# RTS5921 register map
Vendor: Realtek Semiconductor Corp.; Series: RTS5921 Series; File version: 0.01
CPU: ARMV8MBL r0p0, little endian, MPU, no FPU, VTOR, 3 interrupt priority bits
Registers are 32-bit, read-write, reset 0x0 unless marked. A register's access mark holds for its fields unless they carry their own. Offsets are from the block's base; [hi:lo] are bit positions.

## STRIP0 — ARGB LED STRIP Controller
Base 0x40101600
Same registers: STRIP1 0x40101700, STRIP2 0x40101800, STRIP3 0x40101900, STRIP4 0x40101A00, STRIP5 0x40101B00, STRIP6 0x40101C00, STRIP7 0x40101D00
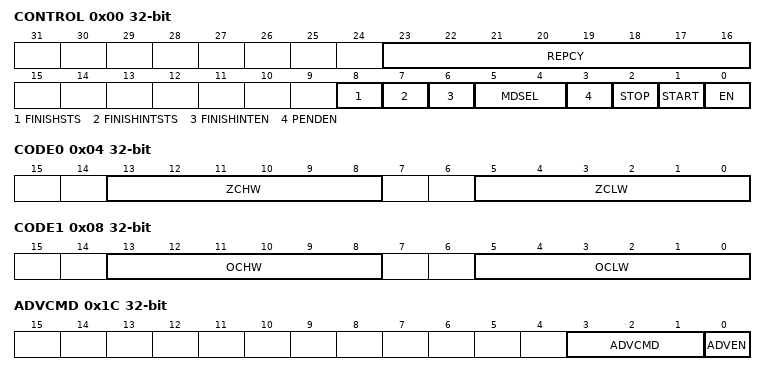
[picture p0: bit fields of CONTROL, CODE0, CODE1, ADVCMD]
0x00 CONTROL — LED STRIP CONTROL REGISTER
  [23:16] REPCY — LED STRIP REPEAT CYCLE. Output strip data size is [REPCY * (TRANSLEN +1)]
  [8] FINISHSTS — LED STRIP FINISH STATUS: 1=Data transfer is finished; 0=interface is idle
    0=Idle (LED STRIP interface is idle); 1=Finished (Data transfer is finished)
  [7] FINISHINTSTS — LED STRIP BUSY INTERRUPT STATUS. W1C clears to 0. 1=Busy flag from 1 to 0
    0=NoEffect; 1=SetOnBusyToIdle (Set when Busy flag from 1 to 0)
  [6] FINISHINTEN — LED STRIP FINISH INTERRUPT ENABLE
    0=Disable Interrupt; 1=Enable Interrupt
  [5:4] MDSEL — LED MODE SELECT
    0=One shot Mode; 1=Repeat Mode; 2=Always Run Mode
  [3] PENDEN — LED STRIP PENDING CODE ENABLE
    0=Disable Pending Code; 1=Enable Pending Code
  [2] STOP — LED STRIP STOP. 1=stop after this transmit cycle is complete
    0=NoEffect; 1=Stop after this cycle
  [1] START — LED STRIP START. 1=Start data buffer transmit. W1C clears
    0=NoEffect; 1=Start LED STRIP data buffer transmit
  [0] EN — LED STRIP ENABLE
    0=Disable LED STRIP Module; 1=Enable LED STRIP Module
0x04 CODE0 — LED STRIP 0 CODE
  [13:8] ZCHW — LED STRIP 0 CODE HIGH WIDTH. Output 0 high time = (ZCHW + 2) * period of clk_fnd (40ns)
  [5:0] ZCLW — LED STRIP 0 CODE LOW WIDTH. Output 0 low time = (ZCLW + 2) * period of clk_fnd (40ns)
0x08 CODE1 — LED STRIP 1 CODE
  [13:8] OCHW — LED STRIP 1 CODE HIGH WIDTH. Output 1 high time = (OCHW + 2) * period of clk_fnd (40ns)
  [5:0] OCLW — LED STRIP 1 CODE LOW WIDTH. Output 1 low time = (OCLW + 2) * period of clk_fnd (40ns)
0x0C RSTW — LED STRIP RESET WIDTH REGISTER
  [31:0] RSTW — LED strip reset time = (RSTW + 1) * period of clk_fnd (40ns). RSTLW [5:0] is treated as 1_11111b internally.
0x10 PENDW — Pending Width Control Register
  [5:0] PENDW — These bits control pending time before the next LED strip data is transferred.
0x14 DSRC — LED STRIP Data Source Address
  [31:0] TRANSADD — Before starting an LED STRIP Transmit, this field must be initialized to contain the Base Address of the buffer in SRAM.
0x18 TRANSLEN — Transmit Length Register
  [13:0] TRANSLEN — Specifies how many bytes are to be transmitted from the Transmit Buffer memory.
0x1C ADVCMD — Advanced Command Register
  [3:1] ADVCMD — Advanced command selector. 0x00: AVD_TH50 0x01: AVD_TH20 0x02: AVD_SLEEP 0x03: AVD_WAKEUP 0x04: AVD_SET_ID 0x05: AVD_CLEAN_ID 0x06: AVD_CHECK_ID 0x07: AVD_SPECIFY_ID
    0=AVD_TH50; 1=AVD_TH20; 2=AVD_SLEEP; 3=AVD_WAKEUP; 4=AVD_SET_ID; 5=AVD_CLEAN_ID; 6=AVD_CHECK_ID; 7=AVD_SPECIFY_ID
  [0] ADVEN — Enable advanced command execution
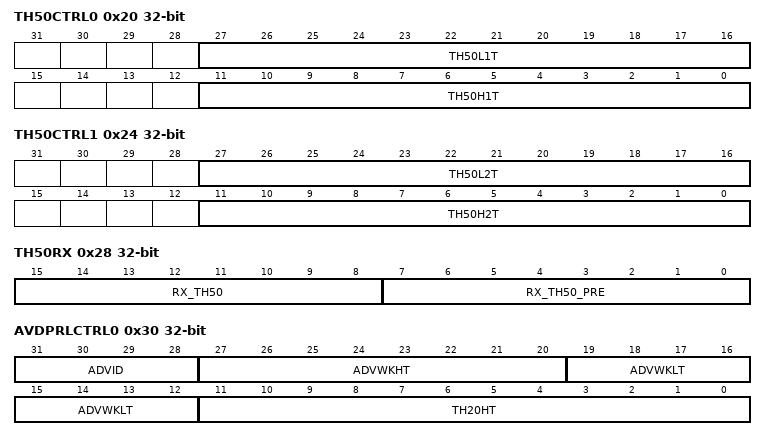
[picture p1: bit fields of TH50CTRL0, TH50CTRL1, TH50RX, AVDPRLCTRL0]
0x20 TH50CTRL0 — ADV_TH50 Command Timing Register
  [27:16] TH50L1T — Indicate the 1st low pulse width (number of count base on 24MHz) of ADV_TH50 command.
  [11:0] TH50H1T — Indicate the 1st high pulse width (number of count base on 24MHz) of ADV_TH50 command.
0x24 TH50CTRL1 — ADV_TH50 2nd Pulse Timing Register
  [27:16] TH50L2T — Indicate the 2nd low pulse width (number of count based on 24MHz) of ADV_TH50 command.
  [11:0] TH50H2T — Indicate the 2nd high pulse width (number of count based on 24MHz) of ADV_TH50 command.
0x28 TH50RX — TH50 Receive Register
  [15:8] RX_TH50 — Received TH50 data (bits 15:8).
  [7:0] RX_TH50_PRE — TH50 pre-received data (bits 7:0).
0x2C TH50TO — ADV_TH50 Timeout Register
  [11:0] TH50TO — Indicate the timeout pulse width (number of count based on 24MHz) of ADV_TH50 command. Exit ADV_TH50 mode when there is no response pulse within the time of TH50TO.
0x30 AVDPRLCTRL0 — ARGB Gen2 Parallel Control Register 0
  [31:28] ADVID — Dynamic ID number for ARGB gen2 parallel mode
  [27:20] ADVWKHT — High pulse width (counts, 24MHz) of ADV_WAKUP command
  [19:12] ADVWKLT — Low pulse width (counts, 24MHz/1024) of ADV_WAKUP command, default ~1ms
  [11:0] TH20HT — High pulse width (counts, 24MHz) of ADV_TH20 command
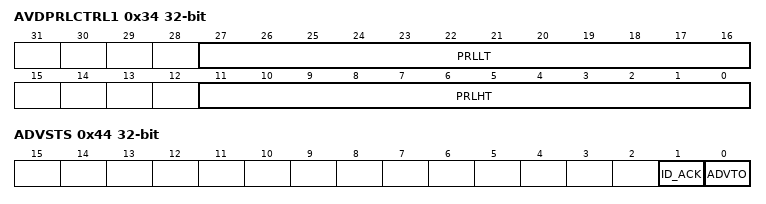
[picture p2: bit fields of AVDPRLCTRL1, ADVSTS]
0x34 AVDPRLCTRL1 — ARGB Gen2 Parallel Control Register 1
  [27:16] PRLLT — Low pulse width (counts, 24MHz) of ADV_SET_ID command
  [11:0] PRLHT — High pulse width (counts, 24MHz) of ADV_SET_ID command
0x38 AVDPRLTO — ADV_SET_ID Timeout Register
  [11:0] PRLTO — Timeout low pulse width (counts, 24MHz) of ADV_SET_ID command
0x3C RECVADDR — SRAM Address for Receiving Gen2 ARGB Data
  [31:0] RECVADDR — SRAM address for receiving Gen2 ARGB data
0x40 RECVCNT — Receive Data Count Register
  [7:0] RECVCNT — Receive data count
0x44 ADVSTS — Status Register
  [1] ID_ACK — ID Acknowledge (W1C)
  [0] ADVTO — Timeout Flag (W1C)
0x48 ADVINT — ADV Interrupt Enable Register
  [0] ADVTOINT_EN — ADV Timeout Interrupt Enable
